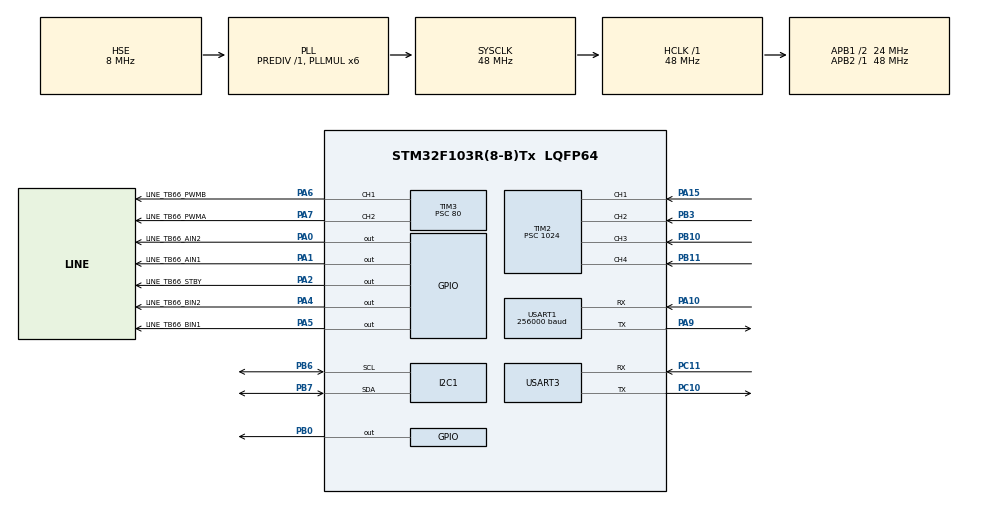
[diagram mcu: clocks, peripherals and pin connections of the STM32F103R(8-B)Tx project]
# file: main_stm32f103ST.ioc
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FREERTOS.HEAP_NUMBER=3
FREERTOS.MEMORY_ALLOCATION=2
FREERTOS.Tasks01=defaultTask,0,128,StartDefaultTask,Default,NULL,Dynamic,NULL,NULL
FREERTOS.configCHECK_FOR_STACK_OVERFLOW=2
FREERTOS.configMAX_PRIORITIES=32
FREERTOS.configTIMER_TASK_STACK_DEPTH=512
FREERTOS.configTOTAL_HEAP_SIZE=700
FREERTOS.configUSE_TIMERS=1
Mcu.Family=STM32F1
Mcu.Name=STM32F103R(8-B)Tx
Mcu.Package=LQFP64
NVIC.PriorityGroup=NVIC_PRIORITYGROUP_4
NVIC.TIM1_UP_IRQn=true\:0\:0\:false\:false\:true\:false\:false\:true
NVIC.TimeBase=TIM1_UP_IRQn
NVIC.TimeBaseIP=TIM1
NVIC.USART3_IRQn=true\:0\:0\:false\:false\:true\:false\:true\:true
PA0-WKUP.GPIO_Label=LINE_TB66_AIN2
PA0-WKUP.Signal=GPIO_Output
PA1.GPIO_Label=LINE_TB66_AIN1
PA1.Signal=GPIO_Output
PA10.Mode=Asynchronous
PA10.Signal=USART1_RX
PA13.Mode=Serial_Wire
PA13.Signal=SYS_JTMS-SWDIO
PA14.Mode=Serial_Wire
PA14.Signal=SYS_JTCK-SWCLK
PA15.Signal=S_TIM2_CH1_ETR
PA2.GPIO_Label=LINE_TB66_STBY
PA2.Signal=GPIO_Output
PA4.GPIO_Label=LINE_TB66_BIN2
PA4.Signal=GPIO_Output
PA5.GPIO_Label=LINE_TB66_BIN1
PA5.Signal=GPIO_Output
PA6.GPIO_Label=LINE_TB66_PWMB
PA6.Signal=S_TIM3_CH1
PA7.GPIO_Label=LINE_TB66_PWMA
PA7.Signal=S_TIM3_CH2
PA9.Mode=Asynchronous
PA9.Signal=USART1_TX
PB0.Signal=GPIO_Output
PB10.Signal=S_TIM2_CH3
PB11.Signal=S_TIM2_CH4
PB3.Signal=S_TIM2_CH2
PB6.Mode=I2C
PB6.Signal=I2C1_SCL
PB7.Mode=I2C
PB7.Signal=I2C1_SDA
PC10.Mode=Asynchronous
PC10.Signal=USART3_TX
PC11.Mode=Asynchronous
PC11.Signal=USART3_RX
PC14-OSC32_IN.Mode=LSE-External-Oscillator
PC14-OSC32_IN.Signal=RCC_OSC32_IN
PC15-OSC32_OUT.Mode=LSE-External-Oscillator
PC15-OSC32_OUT.Signal=RCC_OSC32_OUT
PD0-OSC_IN.Mode=HSE-External-Oscillator
PD0-OSC_IN.Signal=RCC_OSC_IN
PD1-OSC_OUT.Mode=HSE-External-Oscillator
PD1-OSC_OUT.Signal=RCC_OSC_OUT
ProjectManager.HeapSize=0x2500
ProjectManager.StackSize=0x400
ProjectManager.TargetToolchain=STM32CubeIDE
RCC.AHBFreq_Value=48000000
RCC.APB1CLKDivider=RCC_HCLK_DIV2
RCC.APB1Freq_Value=24000000
RCC.APB1TimFreq_Value=48000000
RCC.APB2Freq_Value=48000000
RCC.APB2TimFreq_Value=48000000
RCC.HCLKFreq_Value=48000000
RCC.PLLMUL=RCC_PLL_MUL6
RCC.PLLSourceVirtual=RCC_PLLSOURCE_HSE
RCC.SYSCLKFreq_VALUE=48000000
RCC.SYSCLKSource=RCC_SYSCLKSOURCE_PLLCLK
RCC.USBFreq_Value=48000000
SH.S_TIM2_CH1_ETR.0=TIM2_CH1,Input_Capture1_from_TI1
SH.S_TIM2_CH2.0=TIM2_CH2,Input_Capture2_from_TI2
SH.S_TIM2_CH3.0=TIM2_CH3,Input_Capture3_from_TI3
SH.S_TIM2_CH4.0=TIM2_CH4,Input_Capture4_from_TI4
SH.S_TIM3_CH1.0=TIM3_CH1,PWM Generation1 CH1
SH.S_TIM3_CH2.0=TIM3_CH2,PWM Generation2 CH2
TIM2.AutoReloadPreload=TIM_AUTORELOAD_PRELOAD_ENABLE
TIM2.Channel-Input_Capture1_from_TI1=TIM_CHANNEL_1
TIM2.Channel-Input_Capture2_from_TI2=TIM_CHANNEL_2
TIM2.Channel-Input_Capture3_from_TI3=TIM_CHANNEL_3
TIM2.Channel-Input_Capture4_from_TI4=TIM_CHANNEL_4
TIM2.ICPolarity_CH2=TIM_INPUTCHANNELPOLARITY_FALLING
TIM2.ICPolarity_CH4=TIM_INPUTCHANNELPOLARITY_FALLING
TIM2.Prescaler=1024
TIM3.AutoReloadPreload=TIM_AUTORELOAD_PRELOAD_ENABLE
TIM3.Channel-PWM\ Generation1\ CH1=TIM_CHANNEL_1
TIM3.Channel-PWM\ Generation2\ CH2=TIM_CHANNEL_2
TIM3.CounterMode=TIM_COUNTERMODE_UP
TIM3.Period=2000
TIM3.Prescaler=80
TIM4.AutoReloadPreload=TIM_AUTORELOAD_PRELOAD_ENABLE
TIM4.Prescaler=80
USART1.BaudRate=256000
USART1.Mode=MODE_TX
USART1.VirtualMode=VM_ASYNC
USART3.VirtualMode=VM_ASYNC
VP_FREERTOS_VS_CMSIS_V1.Mode=CMSIS_V1
VP_SYS_VS_tim1.Mode=TIM1
VP_TIM3_VS_ClockSourceINT.Mode=Internal
VP_TIM4_VS_ClockSourceINT.Mode=Internal
board=custom

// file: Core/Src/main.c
/* USER CODE BEGIN Header */
/**
  ******************************************************************************
  * @file           : main.c
  * @brief          : Main program body
  ******************************************************************************
  * @attention
  *
  * <h2><center>&copy; Copyright (c) 2020 STMicroelectronics.
  * All rights reserved.</center></h2>
  *
  * This software component is licensed by ST under BSD 3-Clause license,
  * the "License"; You may not use this file except in compliance with the
  * License. You may obtain a copy of the License at:
  *                        opensource.org/licenses/BSD-3-Clause
  *
  ******************************************************************************
  */
/* USER CODE END Header */
#include "main.h"
#include "cmsis_os.h"
#include "i2c.h"
#include "tim.h"
#include "usart.h"
#include "gpio.h"

/* USER CODE BEGIN PV */
/*void *malloc ( size_t size ){
	void *ptr = pvPortMalloc(size);
	return ptr;
}
void* calloc (size_t num, size_t size) {
	void *ptr = pvPortMalloc(num*size);
	if (ptr != 0) {
		memset(ptr, 0, num*size);
	}
	return ptr;
}
void *realloc( void *ptr, size_t new_size ) {
	vPortFree(ptr);
	ptr = pvPortMalloc(new_size);
	return ptr;
}
void free(void* ptr) {
	vPortFree(ptr);
}
*/
/* USER CODE END PV */

void SystemClock_Config(void);
void MX_FREERTOS_Init(void);

/* USER CODE BEGIN 0 */
int __io_putchar(int ch) {
	HAL_UART_Transmit(&huart1, &ch, 1, 1000);
}

/* USER CODE END 0 */

int main(void)
{

  /* MCU Configuration--------------------------------------------------------*/

  /* Reset of all peripherals, Initializes the Flash interface and the Systick. */
  HAL_Init();

  /* Configure the system clock */
  SystemClock_Config();

  /* Initialize all configured peripherals */
  MX_GPIO_Init();
  MX_TIM3_Init();
  MX_TIM4_Init();
  MX_I2C1_Init();
  MX_TIM2_Init();
  MX_USART3_UART_Init();
  MX_USART1_UART_Init();
  /* USER CODE BEGIN 2 */

  main_cpp();

  /* USER CODE END 2 */

  /* Call init function for freertos objects (in freertos.c) */
  MX_FREERTOS_Init();
  /* Start scheduler */
  osKernelStart();

  /* We should never get here as control is now taken by the scheduler */
  /* Infinite loop */
  while (1)
  {

  }
}

void SystemClock_Config(void)
{
  RCC_OscInitTypeDef RCC_OscInitStruct = {0};
  RCC_ClkInitTypeDef RCC_ClkInitStruct = {0};

  /** Initializes the RCC Oscillators according to the specified parameters
  * in the RCC_OscInitTypeDef structure.
  */
  RCC_OscInitStruct.OscillatorType = RCC_OSCILLATORTYPE_HSE;
  RCC_OscInitStruct.HSEState = RCC_HSE_ON;
  RCC_OscInitStruct.HSEPredivValue = RCC_HSE_PREDIV_DIV1;
  RCC_OscInitStruct.HSIState = RCC_HSI_ON;
  RCC_OscInitStruct.PLL.PLLState = RCC_PLL_ON;
  RCC_OscInitStruct.PLL.PLLSource = RCC_PLLSOURCE_HSE;
  RCC_OscInitStruct.PLL.PLLMUL = RCC_PLL_MUL6;
  if (HAL_RCC_OscConfig(&RCC_OscInitStruct) != HAL_OK)
  {
    Error_Handler();
  }
  /** Initializes the CPU, AHB and APB buses clocks
  */
  RCC_ClkInitStruct.ClockType = RCC_CLOCKTYPE_HCLK|RCC_CLOCKTYPE_SYSCLK
                              |RCC_CLOCKTYPE_PCLK1|RCC_CLOCKTYPE_PCLK2;
  RCC_ClkInitStruct.SYSCLKSource = RCC_SYSCLKSOURCE_PLLCLK;
  RCC_ClkInitStruct.AHBCLKDivider = RCC_SYSCLK_DIV1;
  RCC_ClkInitStruct.APB1CLKDivider = RCC_HCLK_DIV2;
  RCC_ClkInitStruct.APB2CLKDivider = RCC_HCLK_DIV1;

  if (HAL_RCC_ClockConfig(&RCC_ClkInitStruct, FLASH_LATENCY_1) != HAL_OK)
  {
    Error_Handler();
  }
}

void HAL_TIM_PeriodElapsedCallback(TIM_HandleTypeDef *htim)
{
  if (htim->Instance == TIM1) {
    HAL_IncTick();
  }
}

void Error_Handler(void)
{
}

/************************ (C) COPYRIGHT STMicroelectronics *****END OF FILE****/

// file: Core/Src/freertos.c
/* USER CODE BEGIN Header */
/**
  ******************************************************************************
  * File Name          : freertos.c
  * Description        : Code for freertos applications
  ******************************************************************************
  * @attention
  *
  * <h2><center>&copy; Copyright (c) 2020 STMicroelectronics.
  * All rights reserved.</center></h2>
  *
  * This software component is licensed by ST under Ultimate Liberty license
  * SLA0044, the "License"; You may not use this file except in compliance with
  * the License. You may obtain a copy of the License at:
  *                             www.st.com/SLA0044
  *
  ******************************************************************************
  */
/* USER CODE END Header */

#include "FreeRTOS.h"
#include "task.h"
#include "main.h"
#include "cmsis_os.h"

osThreadId defaultTaskHandle;

void StartDefaultTask(void const * argument);

void MX_FREERTOS_Init(void); /* (MISRA C 2004 rule 8.1) */

/* GetIdleTaskMemory prototype (linked to static allocation support) */
void vApplicationGetIdleTaskMemory( StaticTask_t **ppxIdleTaskTCBBuffer, StackType_t **ppxIdleTaskStackBuffer, uint32_t *pulIdleTaskStackSize );

/* GetTimerTaskMemory prototype (linked to static allocation support) */
void vApplicationGetTimerTaskMemory( StaticTask_t **ppxTimerTaskTCBBuffer, StackType_t **ppxTimerTaskStackBuffer, uint32_t *pulTimerTaskStackSize );

/* Hook prototypes */
void vApplicationStackOverflowHook(xTaskHandle xTask, signed char *pcTaskName);

/* USER CODE BEGIN 4 */
__weak void vApplicationStackOverflowHook(xTaskHandle xTask, signed char *pcTaskName)
{
   /* Run time stack overflow checking is performed if
   configCHECK_FOR_STACK_OVERFLOW is defined to 1 or 2. This hook function is
   called if a stack overflow is detected. */
}
/* USER CODE END 4 */

/* USER CODE BEGIN GET_IDLE_TASK_MEMORY */
static StaticTask_t xIdleTaskTCBBuffer;
static StackType_t xIdleStack[configMINIMAL_STACK_SIZE];

void vApplicationGetIdleTaskMemory( StaticTask_t **ppxIdleTaskTCBBuffer, StackType_t **ppxIdleTaskStackBuffer, uint32_t *pulIdleTaskStackSize )
{
  *ppxIdleTaskTCBBuffer = &xIdleTaskTCBBuffer;
  *ppxIdleTaskStackBuffer = &xIdleStack[0];
  *pulIdleTaskStackSize = configMINIMAL_STACK_SIZE;
  /* place for user code */
}
/* USER CODE END GET_IDLE_TASK_MEMORY */

/* USER CODE BEGIN GET_TIMER_TASK_MEMORY */
static StaticTask_t xTimerTaskTCBBuffer;
static StackType_t xTimerStack[configTIMER_TASK_STACK_DEPTH];

void vApplicationGetTimerTaskMemory( StaticTask_t **ppxTimerTaskTCBBuffer, StackType_t **ppxTimerTaskStackBuffer, uint32_t *pulTimerTaskStackSize )
{
  *ppxTimerTaskTCBBuffer = &xTimerTaskTCBBuffer;
  *ppxTimerTaskStackBuffer = &xTimerStack[0];
  *pulTimerTaskStackSize = configTIMER_TASK_STACK_DEPTH;
  /* place for user code */
}
/* USER CODE END GET_TIMER_TASK_MEMORY */

void MX_FREERTOS_Init(void) {

  /* Create the thread(s) */
  /* definition and creation of defaultTask */
  osThreadDef(defaultTask, StartDefaultTask, osPriorityNormal, 0, 128);
  defaultTaskHandle = osThreadCreate(osThread(defaultTask), NULL);

}

void StartDefaultTask(void const * argument)
{
  /* USER CODE BEGIN StartDefaultTask */
	DefaultTask(argument);
  /* USER CODE END StartDefaultTask */
}

/************************ (C) COPYRIGHT STMicroelectronics *****END OF FILE****/
